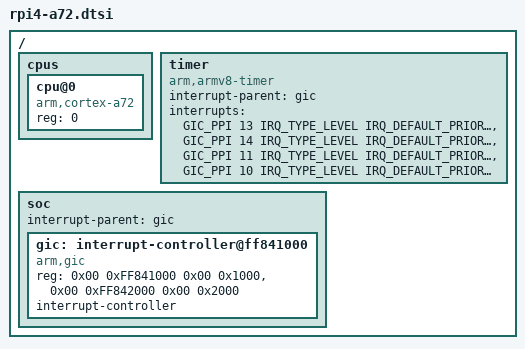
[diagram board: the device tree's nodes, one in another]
/*
 * Copyright (c) 2022 openEule Embedded
 *
 * SPDX-License-Identifier: Apache-2.0
 */

 #include <mem.h>
 #include <arm64/armv8-a.dtsi>
 #include <zephyr/dt-bindings/interrupt-controller/arm-gic.h>

 / {
	#address-cells = <2>;
	#size-cells = <2>;

    cpus {
		#address-cells = <1>;
		#size-cells = <0>;

        cpu@0 {
			device_type = "cpu";
			compatible = "arm,cortex-a72";
			reg = <0>;
		};
     };

    timer {
        compatible = "arm,armv8-timer";
        interrupt-parent = <&gic>;
        interrupts = <GIC_PPI 13 IRQ_TYPE_LEVEL
                	IRQ_DEFAULT_PRIORITY>,
                <GIC_PPI 14 IRQ_TYPE_LEVEL
                	IRQ_DEFAULT_PRIORITY>,
                <GIC_PPI 11 IRQ_TYPE_LEVEL
                	IRQ_DEFAULT_PRIORITY>,
                <GIC_PPI 10 IRQ_TYPE_LEVEL
            		IRQ_DEFAULT_PRIORITY>;
     };

     soc {
        #address-cells = <2>;
        #size-cells = <2>;
        ranges;

        interrupt-parent = <&gic>;

        gic: interrupt-controller@ff841000 {
            compatible = "arm,gic";
            reg = <0x00 0xFF841000 0x00 0x1000>,
				<0x00 0xFF842000 0x00 0x2000>;
            interrupt-controller;
            #interrupt-cells = <4>;
            status = "okay";
        };
    };
 };
